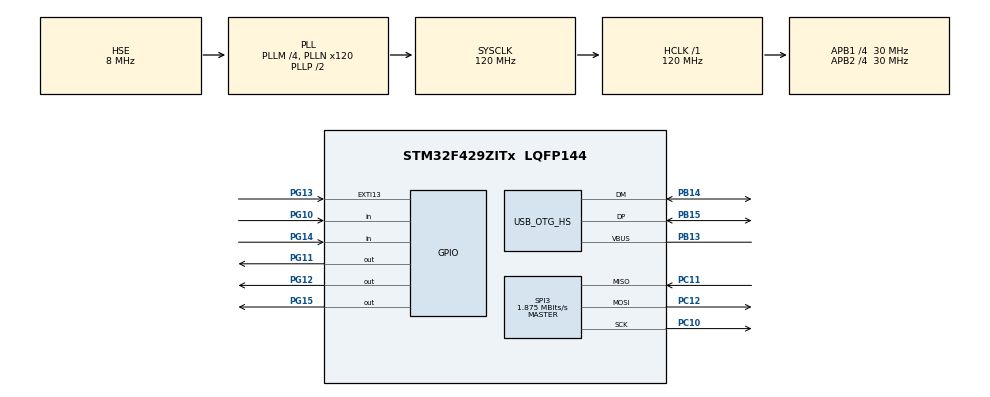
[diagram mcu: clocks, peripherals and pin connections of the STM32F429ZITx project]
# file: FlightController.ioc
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Mcu.Family=STM32F4
Mcu.Name=STM32F429ZITx
Mcu.Package=LQFP144
NVIC.EXTI15_10_IRQn=true\:0\:0\:false\:false\:true\:true
NVIC.OTG_HS_IRQn=true\:0\:0\:false\:false\:true\:false
NVIC.PriorityGroup=NVIC_PRIORITYGROUP_4
PB13.Mode=Activate_VBUS_FS
PB13.Signal=USB_OTG_HS_VBUS
PB14.Mode=Device_Only_FS
PB14.Signal=USB_OTG_HS_DM
PB15.Mode=Device_Only_FS
PB15.Signal=USB_OTG_HS_DP
PC10.Mode=Full_Duplex_Master
PC10.Signal=SPI3_SCK
PC11.Mode=Full_Duplex_Master
PC11.Signal=SPI3_MISO
PC12.Mode=Full_Duplex_Master
PC12.Signal=SPI3_MOSI
PG10.Signal=GPIO_Input
PG11.GPIO_Speed=GPIO_SPEED_FREQ_VERY_HIGH
PG11.Signal=GPIO_Output
PG12.GPIO_Speed=GPIO_SPEED_FREQ_VERY_HIGH
PG12.Signal=GPIO_Output
PG13.Signal=GPXTI13
PG14.Signal=GPIO_Input
PG15.GPIO_Speed=GPIO_SPEED_FREQ_VERY_HIGH
PG15.Signal=GPIO_Output
PH0/OSC_IN.Mode=HSE-External-Oscillator
PH0/OSC_IN.Signal=RCC_OSC_IN
PH1/OSC_OUT.Mode=HSE-External-Oscillator
PH1/OSC_OUT.Signal=RCC_OSC_OUT
ProjectManager.HeapSize=0x200
ProjectManager.StackSize=0x400
ProjectManager.TargetToolchain=SW4STM32
RCC.48MHZClocksFreq_Value=48000000
RCC.AHBFreq_Value=120000000
RCC.APB1CLKDivider=RCC_HCLK_DIV4
RCC.APB1Freq_Value=30000000
RCC.APB1TimFreq_Value=60000000
RCC.APB2CLKDivider=RCC_HCLK_DIV4
RCC.APB2Freq_Value=30000000
RCC.APB2TimFreq_Value=60000000
RCC.CortexFreq_Value=120000000
RCC.HCLKFreq_Value=120000000
RCC.HSE_VALUE=8000000
RCC.HSI_VALUE=16000000
RCC.LSE_VALUE=32768
RCC.PLLM=4
RCC.PLLN=120
RCC.PLLQ=5
RCC.SYSCLKFreq_VALUE=120000000
RCC.SYSCLKSource=RCC_SYSCLKSOURCE_PLLCLK
RCC.VCOOutputFreq_Value=240000000
SPI3.BaudRatePrescaler=SPI_BAUDRATEPRESCALER_16
SPI3.CalculateBaudRate=1.875 MBits/s
SPI3.Direction=SPI_DIRECTION_2LINES
SPI3.Mode=SPI_MODE_MASTER
SPI3.VirtualType=VM_MASTER
USB_DEVICE.CLASS_NAME_HS=CDC
USB_DEVICE.VirtualMode-CDC_HS=Cdc
USB_DEVICE.VirtualModeHS=Cdc_HS
USB_OTG_HS.VirtualMode-Device_Only_FS=Device_Only_FS
VP_USB_DEVICE_VS_USB_DEVICE_CDC_HS.Mode=CDC_HS
board=FlightController

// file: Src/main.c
/**
  ******************************************************************************
  * @file           : main.c
  * @brief          : Main program body
  ******************************************************************************
  * This notice applies to any and all portions of this file
  * that are not between comment pairs USER CODE BEGIN and
  * USER CODE END. Other portions of this file, whether
  * inserted by the user or by software development tools
  * are owned by their respective copyright owners.
  *
  * Copyright (c) 2018 STMicroelectronics International N.V.
  * All rights reserved.
  *
  * Redistribution and use in source and binary forms, with or without
  * modification, are permitted, provided that the following conditions are met:
  *
  * 1. Redistribution of source code must retain the above copyright notice,
  *    this list of conditions and the following disclaimer.
  * 2. Redistributions in binary form must reproduce the above copyright notice,
  *    this list of conditions and the following disclaimer in the documentation
  *    and/or other materials provided with the distribution.
  * 3. Neither the name of STMicroelectronics nor the names of other
  *    contributors to this software may be used to endorse or promote products
  *    derived from this software without specific written permission.
  * 4. This software, including modifications and/or derivative works of this
  *    software, must execute solely and exclusively on microcontroller or
  *    microprocessor devices manufactured by or for STMicroelectronics.
  * 5. Redistribution and use of this software other than as permitted under
  *    this license is void and will automatically terminate your rights under
  *    this license.
  *
  * THIS SOFTWARE IS PROVIDED BY STMICROELECTRONICS AND CONTRIBUTORS "AS IS"
  * AND ANY EXPRESS, IMPLIED OR STATUTORY WARRANTIES, INCLUDING, BUT NOT
  * LIMITED TO, THE IMPLIED WARRANTIES OF MERCHANTABILITY, FITNESS FOR A
  * PARTICULAR PURPOSE AND NON-INFRINGEMENT OF THIRD PARTY INTELLECTUAL PROPERTY
  * RIGHTS ARE DISCLAIMED TO THE FULLEST EXTENT PERMITTED BY LAW. IN NO EVENT
  * SHALL STMICROELECTRONICS OR CONTRIBUTORS BE LIABLE FOR ANY DIRECT, INDIRECT,
  * INCIDENTAL, SPECIAL, EXEMPLARY, OR CONSEQUENTIAL DAMAGES (INCLUDING, BUT NOT
  * LIMITED TO, PROCUREMENT OF SUBSTITUTE GOODS OR SERVICES; LOSS OF USE, DATA,
  * OR PROFITS; OR BUSINESS INTERRUPTION) HOWEVER CAUSED AND ON ANY THEORY OF
  * LIABILITY, WHETHER IN CONTRACT, STRICT LIABILITY, OR TORT (INCLUDING
  * NEGLIGENCE OR OTHERWISE) ARISING IN ANY WAY OUT OF THE USE OF THIS SOFTWARE,
  * EVEN IF ADVISED OF THE POSSIBILITY OF SUCH DAMAGE.
  *
  ******************************************************************************
  */
#include "main.h"
#include "stm32f4xx_hal.h"
#include "usb_device.h"

/* USER CODE BEGIN Includes */
#include "../AT86RF212B/Inc/MainController.h"

/* USER CODE END Includes */

SPI_HandleTypeDef hspi3;

/* USER CODE BEGIN PV */
/* Private variables ---------------------------------------------------------*/

/* USER CODE END PV */

void SystemClock_Config(void);
static void MX_GPIO_Init(void);
static void MX_SPI3_Init(void);

/* USER CODE BEGIN PFP */
/* Private function prototypes -----------------------------------------------*/

/* USER CODE END PFP */

int main(void)
{

  /* MCU Configuration----------------------------------------------------------*/

  /* Reset of all peripherals, Initializes the Flash interface and the Systick. */
  HAL_Init();

  /* Configure the system clock */
  SystemClock_Config();

  /* Initialize all configured peripherals */
  MX_GPIO_Init();
  MX_USB_DEVICE_Init();
  MX_SPI3_Init();
  /* USER CODE BEGIN 2 */
  MainControllerOpen();
  /* USER CODE END 2 */

  /* Infinite loop */
  /* USER CODE BEGIN WHILE */
    while (1)
    {
    	MainControllerLoop();
  /* USER CODE END WHILE */

    }

}

void SystemClock_Config(void)
{

  RCC_OscInitTypeDef RCC_OscInitStruct;
  RCC_ClkInitTypeDef RCC_ClkInitStruct;

    /**Configure the main internal regulator output voltage
    */
  __HAL_RCC_PWR_CLK_ENABLE();

  __HAL_PWR_VOLTAGESCALING_CONFIG(PWR_REGULATOR_VOLTAGE_SCALE3);

    /**Initializes the CPU, AHB and APB busses clocks
    */
  RCC_OscInitStruct.OscillatorType = RCC_OSCILLATORTYPE_HSE;
  RCC_OscInitStruct.HSEState = RCC_HSE_ON;
  RCC_OscInitStruct.PLL.PLLState = RCC_PLL_ON;
  RCC_OscInitStruct.PLL.PLLSource = RCC_PLLSOURCE_HSE;
  RCC_OscInitStruct.PLL.PLLM = 4;
  RCC_OscInitStruct.PLL.PLLN = 120;
  RCC_OscInitStruct.PLL.PLLP = RCC_PLLP_DIV2;
  RCC_OscInitStruct.PLL.PLLQ = 5;
  if (HAL_RCC_OscConfig(&RCC_OscInitStruct) != HAL_OK)
  {
    _Error_Handler(__FILE__, __LINE__);
  }

    /**Initializes the CPU, AHB and APB busses clocks
    */
  RCC_ClkInitStruct.ClockType = RCC_CLOCKTYPE_HCLK|RCC_CLOCKTYPE_SYSCLK
                              |RCC_CLOCKTYPE_PCLK1|RCC_CLOCKTYPE_PCLK2;
  RCC_ClkInitStruct.SYSCLKSource = RCC_SYSCLKSOURCE_PLLCLK;
  RCC_ClkInitStruct.AHBCLKDivider = RCC_SYSCLK_DIV1;
  RCC_ClkInitStruct.APB1CLKDivider = RCC_HCLK_DIV4;
  RCC_ClkInitStruct.APB2CLKDivider = RCC_HCLK_DIV4;

  if (HAL_RCC_ClockConfig(&RCC_ClkInitStruct, FLASH_LATENCY_3) != HAL_OK)
  {
    _Error_Handler(__FILE__, __LINE__);
  }

    /**Configure the Systick interrupt time
    */
  HAL_SYSTICK_Config(HAL_RCC_GetHCLKFreq()/1000);

    /**Configure the Systick
    */
  HAL_SYSTICK_CLKSourceConfig(SYSTICK_CLKSOURCE_HCLK);

  /* SysTick_IRQn interrupt configuration */
  HAL_NVIC_SetPriority(SysTick_IRQn, 0, 0);
}

/* SPI3 init function */
static void MX_SPI3_Init(void)
{

  /* SPI3 parameter configuration*/
  hspi3.Instance = SPI3;
  hspi3.Init.Mode = SPI_MODE_MASTER;
  hspi3.Init.Direction = SPI_DIRECTION_2LINES;
  hspi3.Init.DataSize = SPI_DATASIZE_8BIT;
  hspi3.Init.CLKPolarity = SPI_POLARITY_LOW;
  hspi3.Init.CLKPhase = SPI_PHASE_1EDGE;
  hspi3.Init.NSS = SPI_NSS_SOFT;
  hspi3.Init.BaudRatePrescaler = SPI_BAUDRATEPRESCALER_16;
  hspi3.Init.FirstBit = SPI_FIRSTBIT_MSB;
  hspi3.Init.TIMode = SPI_TIMODE_DISABLE;
  hspi3.Init.CRCCalculation = SPI_CRCCALCULATION_DISABLE;
  hspi3.Init.CRCPolynomial = 10;
  if (HAL_SPI_Init(&hspi3) != HAL_OK)
  {
    _Error_Handler(__FILE__, __LINE__);
  }

}

/** Configure pins as
        * Analog
        * Input
        * Output
        * EVENT_OUT
        * EXTI
*/
static void MX_GPIO_Init(void)
{

  GPIO_InitTypeDef GPIO_InitStruct;

  /* GPIO Ports Clock Enable */
  __HAL_RCC_GPIOH_CLK_ENABLE();
  __HAL_RCC_GPIOB_CLK_ENABLE();
  __HAL_RCC_GPIOC_CLK_ENABLE();
  __HAL_RCC_GPIOG_CLK_ENABLE();

  /*Configure GPIO pin Output Level */
  HAL_GPIO_WritePin(GPIOG, GPIO_PIN_11|GPIO_PIN_12|GPIO_PIN_15, GPIO_PIN_RESET);

  /*Configure GPIO pins : PG10 PG14 */
  GPIO_InitStruct.Pin = GPIO_PIN_10|GPIO_PIN_14;
  GPIO_InitStruct.Mode = GPIO_MODE_INPUT;
  GPIO_InitStruct.Pull = GPIO_NOPULL;
  HAL_GPIO_Init(GPIOG, &GPIO_InitStruct);

  /*Configure GPIO pins : PG11 PG12 PG15 */
  GPIO_InitStruct.Pin = GPIO_PIN_11|GPIO_PIN_12|GPIO_PIN_15;
  GPIO_InitStruct.Mode = GPIO_MODE_OUTPUT_PP;
  GPIO_InitStruct.Pull = GPIO_NOPULL;
  GPIO_InitStruct.Speed = GPIO_SPEED_FREQ_VERY_HIGH;
  HAL_GPIO_Init(GPIOG, &GPIO_InitStruct);

  /*Configure GPIO pin : PG13 */
  GPIO_InitStruct.Pin = GPIO_PIN_13;
  GPIO_InitStruct.Mode = GPIO_MODE_IT_RISING;
  GPIO_InitStruct.Pull = GPIO_NOPULL;
  HAL_GPIO_Init(GPIOG, &GPIO_InitStruct);

  /* EXTI interrupt init*/
  HAL_NVIC_SetPriority(EXTI15_10_IRQn, 0, 0);
  HAL_NVIC_EnableIRQ(EXTI15_10_IRQn);

}

void _Error_Handler(char *file, int line)
{
  while(1)
  {
  }
}

/************************ (C) COPYRIGHT STMicroelectronics *****END OF FILE****/
